# PER_PRM register map
Vendor: Texas Instruments
Peripheral module from a debugger description file (folder omap36xx).
Registers are 32-bit, access per field, reset 0x7EFFF unless marked. A register's access mark holds for its fields unless they carry their own. Offsets are as the file gives them; lines under a group give offsets from that group; [hi:lo] are bit positions; {n}, {i} and the like mark numbered series; 'fields as' and 'values as' point back to an identical list; <NAME> marks a mode.

## PER_PRM
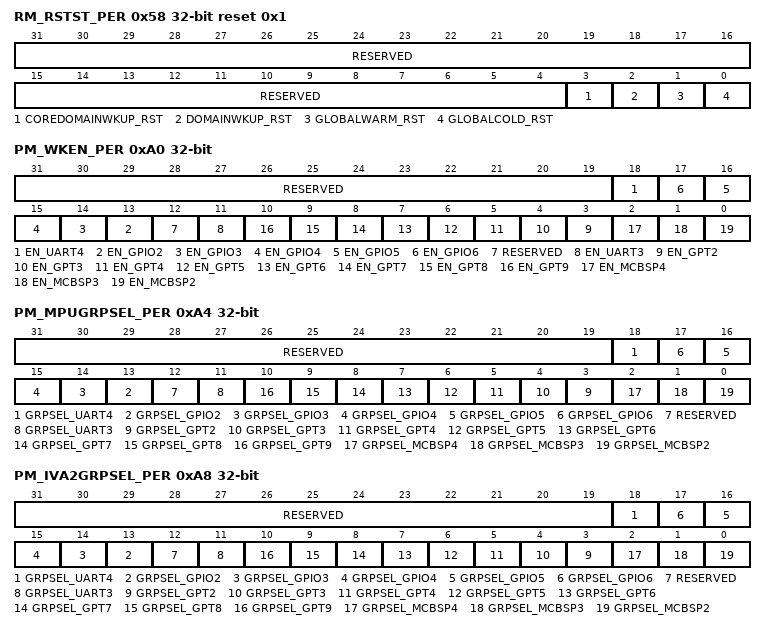
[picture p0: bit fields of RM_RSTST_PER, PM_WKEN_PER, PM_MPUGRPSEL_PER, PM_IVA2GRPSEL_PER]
0x58 RM_RSTST_PER reset 0x1 — This register logs the different reset sources of the PERIPHERAL domain. Each bit is set upon release of the domain reset signal. Must be cleared by software.
  [31:4] RESERVED ro — Write 0s for future compatibility. Read returns 0.
  [3] COREDOMAINWKUP_RST rw — CORE domain wake-up reset
    0=COREDOMAINWKUP_RST_0_r (No power domain wake-up reset.); 0=COREDOMAINWKUP_RST_0_w (Status bit unchanged); 1=COREDOMAINWKUP_RST_1_r (PER domain has been reset following a CORE power domain wake-up from OFF to ON.); 1=COREDOMAINWKUP_RST_1_w (Status bit is cleared to 0.)
  [2] DOMAINWKUP_RST rw — Power domain wake-up reset
    0=DOMAINWKUP_RST_0_r (No power domain wake-up reset.); 0=DOMAINWKUP_RST_0_w (Status bit unchanged); 1=DOMAINWKUP_RST_1_r (PER domain has been reset following a PERIPHERAL power domain wake-up.); 1=DOMAINWKUP_RST_1_w (Status bit is cleared to 0.)
  [1] GLOBALWARM_RST rw — Global warm reset
    0=GLOBALWARM_RST_0_r (No global warm reset.); 0=GLOBALWARM_RST_0_w (Status bit unchanged); 1=GLOBALWARM_RST_1_r (PER domain has been reset upon a global warm reset); 1=GLOBALWARM_RST_1_w (Status bit is cleared to 0.)
  [0] GLOBALCOLD_RST rw — Global cold reset
    0=GLOBALCOLD_RST_0_r (No global cold reset.); 0=GLOBALCOLD_RST_0_w (Status bit unchanged); 1=GLOBALCOLD_RST_1_r (PER domain has been reset upon a global cold reset); 1=GLOBALCOLD_RST_1_w (Status bit is cleared to 0.)
0xA0 PM_WKEN_PER — This register allows enabling/disabling modules wake-up events.
  [31:19] RESERVED ro — Write 0s for future compatibility. Read returns 0.
  [18] EN_UART4 rw — UART 4 wake-up control
    0=UART 4 wake-up is disabled; 1=UART 4 wake-up event is enabled
  [n+11] EN_GPIO{n} rw (n=2..6) — GPIO {n} wake-up control
    0=GPIO {n} wake-up is disabled; 1=GPIO {n} wake-up event is enabled
  [12] RESERVED ro — Write 0s for future compatibility. Read returns 0.
  [11] EN_UART3 rw — UART 3 wake-up control
    0=UART 3 wake-up is disabled; 1=UART 3 wake-up event is enabled
  [n+1] EN_GPT{n} rw (n=2..9) — GPTIMER {n} wake-up control
    0=GPTIMER {n} wake-up is disabled; 1=GPTIMER {n} wake-up event is enabled
  [2] EN_MCBSP4 rw — McBSP 4 wake-up control
    0=McBSP 4 wake-up is disabled; 1=McBSP 4 wake-up event is enabled
  [1] EN_MCBSP3 rw — McBSP3 wake-up control
    0=McBSP 3 wake-up is disabled; 1=McBSP 3 wake-up event is enabled
  [0] EN_MCBSP2 rw — McBSP 2 wake-up control
    0=McBSP 2 wake-up is disabled; 1=McBSP 2 wake-up event is enabled
0xA4 PM_MPUGRPSEL_PER — This register allows selecting the group of modules that wake-up the MPU.
  [31:19] RESERVED ro — Write 0s for future compatibility. Read returns 0.
  [18] GRPSEL_UART4 rw — Select the UART 4 in the MPU wake-up events group
    0=UART 4 is not attached to the MPU wake-up events group; 1=UART 4 is attached to the MPU wake-up events group
  [n+11] GRPSEL_GPIO{n} rw (n=2..6) — Select the GPIO {n} in the MPU wake-up events group
    0=GPIO {n} is not attached to the MPU wake-up events group; 1=GPIO {n} is attached to the MPU wake-up events group
  [12] RESERVED ro — Write 0s for future compatibility. Read returns 0.
  [11] GRPSEL_UART3 rw — Select the UART 3 in the MPU wake-up events group
    0=UART 3 is not attached to the MPU wake-up events group; 1=UART 3 is attached to the MPU wake-up events group
  [n+1] GRPSEL_GPT{n} rw (n=2..9) — Select the GPTIMER {n} in the MPU wake-up events group
    0=GPTIMER {n} is not attached to the MPU wake-up events group; 1=GPTIMER {n} is attached to the MPU wake-up events group
  [2] GRPSEL_MCBSP4 rw — Select the McBSP 4 in the MPU wake-up events group
    0=McBSP 4 is not attached to the MPU wake-up events group; 1=McBSP 4 is attached to the MPU wake-up events group
  [1] GRPSEL_MCBSP3 rw — Select the McBSP 3 in the MPU wake-up events group
    0=McBSP 3 is not attached to the MPU wake-up events group; 1=McBSP 3 is attached to the MPU wake-up events group
  [0] GRPSEL_MCBSP2 rw — Select the McBSP 2 in the MPU wake-up events group
    0=McBSP 2 is not attached to the MPU wake-up events group; 1=McBSP 2 is attached to the MPU wake-up events group
0xA8 PM_IVA2GRPSEL_PER — This register allows selecting the group of modules that wake-up the IVA2.
  [31:19] RESERVED ro — Write 0s for future compatibility. Read returns 0.
  [18] GRPSEL_UART4 rw — Select the UART 4 in the IVA2 wake-up events group
    0=UART 4 is not attached to the IVA2 wake-up events group; 1=UART 4 is attached to the IVA2 wake-up events group
  [n+11] GRPSEL_GPIO{n} rw (n=2..6) — Select the GPIO {n} in the IVA2 wake-up events group
    0=GPIO {n} is not attached to the IVA2 wake-up events group; 1=GPIO {n} is attached to the IVA2 wake-up events group
  [12] RESERVED ro — Write 0s for future compatibility. Read returns 0.
  [11] GRPSEL_UART3 rw — Select the UART 3 in the IVA2 wake-up events group
    0=UART 3 is not attached to the IVA2 wake-up events group; 1=UART 3 is attached to the IVA2 wake-up events group
  [n+1] GRPSEL_GPT{n} rw (n=2..9) — Select the GPTIMER {n} in the IVA2 wake-up events group
    0=GPTIMER {n} is not attached to the IVA2 wake-up events group; 1=GPTIMER {n} is attached to the IVA2 wake-up events group
  [2] GRPSEL_MCBSP4 rw — Select the McBSP 4 in the IVA2 wake-up events group
    0=McBSP 4 is not attached to the IVA2 wake-up events group; 1=McBSP 4 is attached to the IVA2 wake-up events group
  [1] GRPSEL_MCBSP3 rw — Select the McBSP 3 in the IVA2 wake-up events group
    0=McBSP 3 is not attached to the IVA2 wake-up events group; 1=McBSP 3 is attached to the IVA2 wake-up events group
  [0] GRPSEL_MCBSP2 rw — Select the McBSP 2 in the IVA2 wake-up events group
    0=McBSP 2 is not attached to the IVA2 wake-up events group; 1=McBSP 2 is attached to the IVA2 wake-up events group
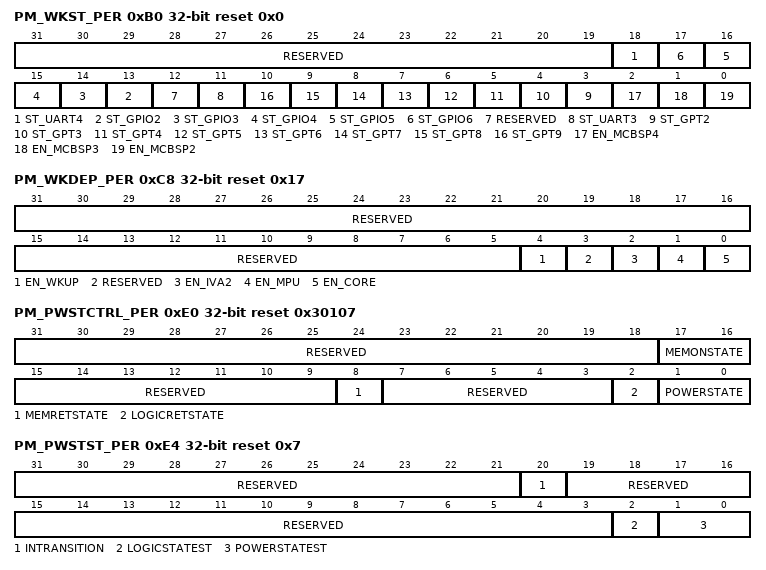
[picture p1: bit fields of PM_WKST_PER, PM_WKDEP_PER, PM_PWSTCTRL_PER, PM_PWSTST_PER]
0xB0 PM_WKST_PER reset 0x0 — This register logs module wake-up events. Must be cleared by software. If it is not cleared, it prevents further domain transition.
  [31:19] RESERVED ro — Write 0s for future compatibility. Read returns 0.
  [18] ST_UART4 rw — UART 4 Wake-up status
    0=ST_UART4_0_r (UART 4 wake-up did not occur or was masked.); 0=ST_UART4_0_w (Status bit unchanged); 1=ST_UART4_1_r (UART 4 wake-up occurred.); 1=ST_UART4_1_w (Status bit is cleared to 0.)
  [n+11] ST_GPIO{n} rw (n=2..6) — GPIO {n} Wake-up status
    0=ST_GPIO{n}_0_r (GPIO {n} wake-up did not occur or was masked.); 0=ST_GPIO{n}_0_w (Status bit unchanged); 1=ST_GPIO{n}_1_r (GPIO {n} wake-up occurred.); 1=ST_GPIO{n}_1_w (Status bit is cleared to 0.)
  [12] RESERVED ro — Write 0s for future compatibility. Read returns 0.
  [11] ST_UART3 rw — UART 3 Wake-up status
    0=ST_UART3_0_r (UART 3 wake-up did not occur or was masked.); 0=ST_UART3_0_w (Status bit unchanged); 1=ST_UART3_1_r (UART 3 wake-up occurred.); 1=ST_UART3_1_w (Status bit is cleared to 0.)
  [n+1] ST_GPT{n} rw (n=2..9) — GPTIMER {n} Wake-up status
    0=ST_GPT{n}_0_r (GPTIMER {n} wake-up did not occur or was masked.); 0=ST_GPT{n}_0_w (Status bit unchanged); 1=ST_GPT{n}_1_r (GPTIMER {n} wake-up occurred.); 1=ST_GPT{n}_1_w (Status bit is cleared to 0.)
  [2] EN_MCBSP4 rw — McBSP 4 Wake-up status
    0=EN_MCBSP4_0_r (McBSP 4 wake-up did not occur or was masked.); 0=EN_MCBSP4_0_w (Status bit unchanged); 1=EN_MCBSP4_1_r (McBSP 4 wake-up occurred.); 1=EN_MCBSP4_1_w (Status bit is cleared to 0.)
  [1] EN_MCBSP3 rw — McBSP3 Wake-up status
    0=EN_MCBSP3_0_r (McBSP 3 wake-up did not occur or was masked.); 0=EN_MCBSP3_0_w (Status bit unchanged); 1=EN_MCBSP3_1_r (McBSP 3 wake-up occurred.); 1=EN_MCBSP3_1_w (Status bit is cleared to 0.)
  [0] EN_MCBSP2 rw — McBSP 2 Wake-up status
    0=EN_MCBSP2_0_r (McBSP 2 wake-up did not occur or was masked.); 0=EN_MCBSP2_0_w (Status bit unchanged); 1=EN_MCBSP2_1_r (McBSP 2 wake-up occurred.); 1=EN_MCBSP2_1_w (Status bit is cleared to 0.)
0xC8 PM_WKDEP_PER reset 0x17 — This register allows enabling or disabling the wake-up of the PER domain upon another domain wakeup events.
  [31:5] RESERVED ro — Write 0s for future compatibility. Read returns 0.
  [4] EN_WKUP rw — WAKEUP domain dependency
    0=PER domain is independent of WKUP domain wake-up event; 1=PER domain is woken-up upon WKUP domain wake-up event
  [3] RESERVED ro — Write 0s for future compatibility. Read returns 0.
  [2] EN_IVA2 rw — IVA2 domain dependency
    0=PER domain is independent of IVA2 domain wake-up event; 1=PER domain is woken-up upon IVA2 domain wake-up event
  [1] EN_MPU rw — MPU domain dependency
    0=PER domain is independent of MPU domain wake-up event; 1=PER domain is is woken-up upon MPU domain wake-up event
  [0] EN_CORE rw — CORE domain dependency (CORE-L3 clock domain only, not CORE-L4)
    0=PER domain is independent of CORE domain wake-up event (CORE-L3 clock domain only, not CORE-L4); 1=PER domain is woken-up upon CORE domain wake-up event
0xE0 PM_PWSTCTRL_PER reset 0x30107 — This register controls the PER domain power state transition.
  [31:18] RESERVED ro — Write 0s for future compatibility. Read returns 0.
  [17:16] MEMONSTATE ro — Memory state when ON
    3=Memory is always ON when domain is ON
  [15:9] RESERVED ro — Write 0s for future compatibility. Read returns 0.
  [8] MEMRETSTATE ro — Memory state when RETENTION
    1=Memory is always retained when domain is in RETENTION state
  [7:3] RESERVED ro — Write 0s for future compatibility. Read returns 0.
  [2] LOGICRETSTATE rw — Logic state when domain is RETENTION
    0=Logic build with retention flip-flop (GPIO) is retained and remaining logic is OFF when domain is in RETENTION state; 1=Logic is retained when domain is in RETENTION state
  [1:0] POWERSTATE rw — Power state control
    0=OFF state; 1=RETENTION state; 3=ON state
0xE4 PM_PWSTST_PER ro reset 0x7 — This register provides a status on the power state transition of the PERIPHERAL domain.
  [31:21] RESERVED — Write 0s for future compatibility. Read returns 0.
  [20] INTRANSITION — Domain transition status
    0=No transition; 1=PERIPHERAL power domain transition is in progress
  [19:3] RESERVED — Write 0s for future compatibility. Read returns 0.
  [2] LOGICSTATEST — Logic state status
    0=PER domain logic is OFF; 1=PER domain logic is ON
  [1:0] POWERSTATEST — Current power state status
    0=Power domain is OFF; 1=Power domain is in RETENTION; 2=Power domain is INACTIVE; 3=Power domain is ON
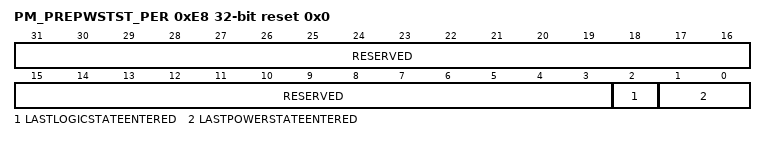
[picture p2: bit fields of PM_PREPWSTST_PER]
0xE8 PM_PREPWSTST_PER reset 0x0 — This register provides a status on the PER domain previous power state. It indicates the state entered during the last sleep transition.
  [31:3] RESERVED ro — Write 0s for future compatibility. Read returns 0.
  [2] LASTLOGICSTATEENTERED rw
    0=PER domain logic was previously OFF; 1=PER domain logic was previously ON
  [1:0] LASTPOWERSTATEENTERED rw
    0=PER domain was previously OFF; 1=PER domain was previously in RETENTION; 2=PER domain was previously INACTIVE; 3=PER domain was previously ON
